# MKL33Z4 register map
Vendor: Freescale Semiconductor, Inc.; Series: Kinetis_L; File version: 1.6
CPU: CM0PLUS r0p0, little endian, no MPU, no FPU, VTOR, 2 interrupt priority bits
Registers are 32-bit, read-write, reset 0x0 unless marked. A register's access mark holds for its fields unless they carry their own. Offsets are from the block's base; [hi:lo] are bit positions; {n}, {i} and the like mark numbered series; 'fields as' and 'values as' point back to an identical list.

## PORTB — Pin Control and Interrupts
Base 0x4004A000; register names take the prefix PORTB_
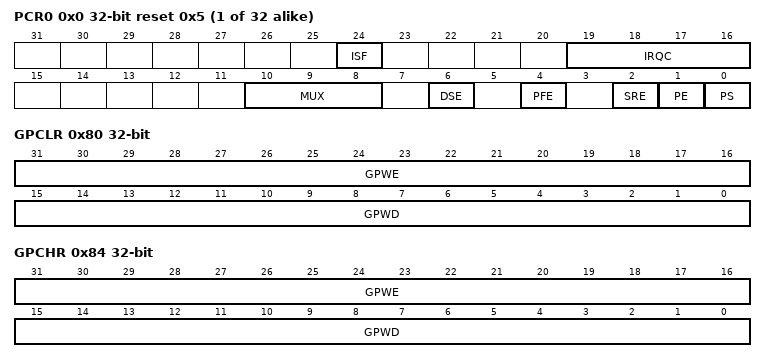
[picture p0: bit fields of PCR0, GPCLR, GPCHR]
{0x0+4i} PCR{i} (i=0..31) reset 0x5 — Pin Control Register n
  [24] ISF — Interrupt Status Flag
    0=Configured interrupt is not detected; 1=Configured interrupt is detected. If the pin is configured to generate a DMA request, then the corresponding flag will be cleared automatically at the completion of the requested DMA transfer. Otherwise, the flag remains set until a logic 1 is written to the flag. If the pin is configured for a level sensitive interrupt and the pin remains asserted, then the flag is set again immediately after it is cleared.
  [19:16] IRQC — Interrupt Configuration
    0=Interrupt/DMA request disabled; 1=DMA request on rising edge; 2=DMA request on falling edge; 3=DMA request on either edge; 8=Interrupt when logic 0; 9=Interrupt on rising-edge; 10=Interrupt on falling-edge; 11=Interrupt on either edge; 12=Interrupt when logic 1
  [10:8] MUX — Pin Mux Control
    0=Pin disabled (analog); 1=Alternative 1 (GPIO); {v}=Alternative {v} (chip-specific) (v=2..7)
  [6] DSE — Drive Strength Enable
    0=Low drive strength is configured on the corresponding pin, if pin is configured as a digital output; 1=High drive strength is configured on the corresponding pin, if pin is configured as a digital output
  [4] PFE — Passive Filter Enable
    0=Passive input filter is disabled on the corresponding pin; 1=Passive input filter is enabled on the corresponding pin, if the pin is configured as a digital input. Refer to the device data sheet for filter characteristics.
  [2] SRE — Slew Rate Enable
    0=Fast slew rate is configured on the corresponding pin, if the pin is configured as a digital output; 1=Slow slew rate is configured on the corresponding pin, if the pin is configured as a digital output
  [1] PE — Pull Enable
    0=Internal pullup or pulldown resistor is not enabled on the corresponding pin; 1=Internal pullup or pulldown resistor is enabled on the corresponding pin, if the pin is configured as a digital input
  [0] PS — Pull Select
    0=Internal pulldown resistor is enabled on the corresponding pin, if the corresponding PE field is set; 1=Internal pullup resistor is enabled on the corresponding pin, if the corresponding PE field is set
0x80 GPCLR wo — Global Pin Control Low Register
  [31:16] GPWE — Global Pin Write Enable
    0=Corresponding Pin Control Register is not updated with the value in GPWD; 1=Corresponding Pin Control Register is updated with the value in GPWD
  [15:0] GPWD — Global Pin Write Data
0x84 GPCHR wo — Global Pin Control High Register
  fields as GPCLR
0xA0 ISFR — Interrupt Status Flag Register
  [31:0] ISF — Interrupt Status Flag
    values as PCR0.ISF

## PORTC — Pin Control and Interrupts
Base 0x4004B000; register names take the prefix PORTC_
Registers as PORTB.

## PORTD — Pin Control and Interrupts
Base 0x4004C000; register names take the prefix PORTD_
Registers as PORTB.

## PORTE — Pin Control and Interrupts
Base 0x4004D000; register names take the prefix PORTE_
Registers as PORTB.

## MCG — Multipurpose Clock Generator Lite
Base 0x40064000; register names take the prefix MCG_
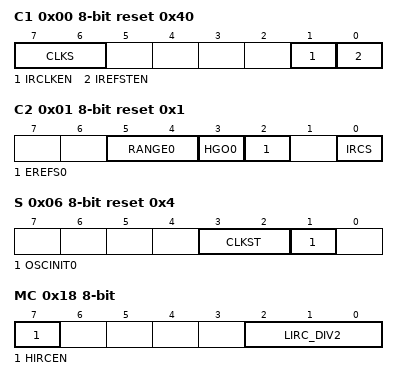
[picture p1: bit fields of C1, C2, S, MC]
0x00 C1 8-bit reset 0x40 — MCG Control Register 1
  [7:6] CLKS — Clock Source Select
    0=Selects HIRC clock as the main clock source. This is HIRC mode.; 1=Selects LIRC clock as the main clock source. This is LIRC2M or LIRC8M mode.; 2=Selects external clock as the main clock source. This is EXT mode.; 3=Reserved. Writing 11 takes no effect.
  [1] IRCLKEN — Internal Reference Clock Enable
    0=LIRC is disabled; 1=LIRC is enabled
  [0] IREFSTEN — Internal Reference Stop Enable
    0=LIRC is disabled in Stop mode; 1=LIRC is enabled in Stop mode, if IRCLKEN is set
0x01 C2 8-bit reset 0x1 — MCG Control Register 2
  [5:4] RANGE0 — External Clock Source Frequency Range Select
    0=Low frequency range selected for the crystal oscillator or the external clock source; 1=High frequency range selected for the crystal oscillator or the external clock source; 2=Very high frequency range selected for the crystal oscillator or the external clock source; 3=Very high frequency range selected for the crystal oscillator or the external clock source. Same effect as 10.
  [3] HGO0 — Crystal Oscillator Operation Mode Select
    0=Configure crystal oscillator for low-power operation; 1=Configure crystal oscillator for high-gain operation
  [2] EREFS0 — External Clock Source Select
    0=External clock requested; 1=Oscillator requested
  [0] IRCS — Low-frequency Internal Reference Clock Select
    0=LIRC is in 2 MHz mode; 1=LIRC is in 8 MHz mode
0x06 S 8-bit ro reset 0x4 — MCG Status Register
  [3:2] CLKST — Clock Mode Status
    0=HIRC clock is selected as the main clock source, and MCG_Lite works at HIRC mode; 1=LIRC clock is selected as the main clock source, and MCG_Lite works at LIRC2M or LIRC8M mode; 2=External clock is selected as the main clock source, and MCG_Lite works at EXT mode
  [1] OSCINIT0 — OSC Initialization Status
    0=OSC is not ready; 1=OSC clock is ready
0x08 SC 8-bit — MCG Status and Control Register
  [3:1] FCRDIV — Low-frequency Internal Reference Clock Divider
    0=Division factor is 1; 1=Division factor is 2; 2=Division factor is 4; 3=Division factor is 8; 4=Division factor is 16; 5=Division factor is 32; 6=Division factor is 64; 7=Division factor is 128
0x14 HCTRIM 8-bit ro reset not defined — MCG High-frequency IRC Coarse Trim Register
  [5:0] COARSE_TRIM — High-frequency IRC Coarse Trim
0x15 HTTRIM 8-bit ro reset not defined — MCG High-frequency IRC Tempco (Temperature Coefficient) Trim Register
  [4:0] TEMPCO_TRIM — High-frequency IRC Tempco Trim
0x16 HFTRIM 8-bit ro reset not defined — MCG High-frequency IRC Fine Trim Register
  [6:0] FINE_TRIM — High-frequency IRC Fine Trim
0x18 MC 8-bit — MCG Miscellaneous Control Register
  [7] HIRCEN — High-frequency IRC Enable
    0=HIRC source is not enabled; 1=HIRC source is enabled
  [2:0] LIRC_DIV2 — Second Low-frequency Internal Reference Clock Divider
    values as SC.FCRDIV
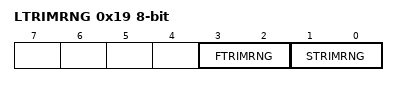
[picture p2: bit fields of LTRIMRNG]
0x19 LTRIMRNG 8-bit ro reset not defined — MCG Low-frequency IRC Trim Range Register
  [3:2] FTRIMRNG — LIRC Fast TRIM (8 MHz) Range
    0=Frequency shift by 10%; 1=No frequency shift; 2=No frequency shift; 3=Frequency shift by -10%
  [1:0] STRIMRNG — LIRC Slow TRIM (2 MHz) Range
    values as FTRIMRNG
0x1A LFTRIM 8-bit ro reset not defined — MCG Low-frequency IRC8M Trim Register
  [6:0] LIRC_FTRIM — LIRC8M TRIM
0x1B LSTRIM 8-bit ro reset not defined — MCG Low-frequency IRC2M Trim Register
  [6:0] LIRC_STRIM — LIRC2M TRIM

## Notices in the file
Redistribution and use in source and binary forms, with or without modification,
are permitted provided that the following conditions are met:
o Redistributions of source code must retain the above copyright notice, this list
of conditions and the following disclaimer.
o Redistributions in binary form must reproduce the above copyright notice, this
list of conditions and the following disclaimer in the documentation and/or
other materials provided with the distribution.
o Neither the name of Freescale Semiconductor, Inc. nor the names of its
contributors may be used to endorse or promote products derived from this
software without specific prior written permission.
THIS SOFTWARE IS PROVIDED BY THE COPYRIGHT HOLDERS AND CONTRIBUTORS "AS IS" AND
ANY EXPRESS OR IMPLIED WARRANTIES, INCLUDING, BUT NOT LIMITED TO, THE IMPLIED
WARRANTIES OF MERCHANTABILITY AND FITNESS FOR A PARTICULAR PURPOSE ARE
DISCLAIMED. IN NO EVENT SHALL THE COPYRIGHT HOLDER OR CONTRIBUTORS BE LIABLE FOR
ANY DIRECT, INDIRECT, INCIDENTAL, SPECIAL, EXEMPLARY, OR CONSEQUENTIAL DAMAGES
(INCLUDING, BUT NOT LIMITED TO, PROCUREMENT OF SUBSTITUTE GOODS OR SERVICES;
LOSS OF USE, DATA, OR PROFITS; OR BUSINESS INTERRUPTION) HOWEVER CAUSED AND ON
ANY THEORY OF LIABILITY, WHETHER IN CONTRACT, STRICT LIABILITY, OR TORT
(INCLUDING NEGLIGENCE OR OTHERWISE) ARISING IN ANY WAY OUT OF THE USE OF THIS
SOFTWARE, EVEN IF ADVISED OF THE POSSIBILITY OF SUCH DAMAGE.
